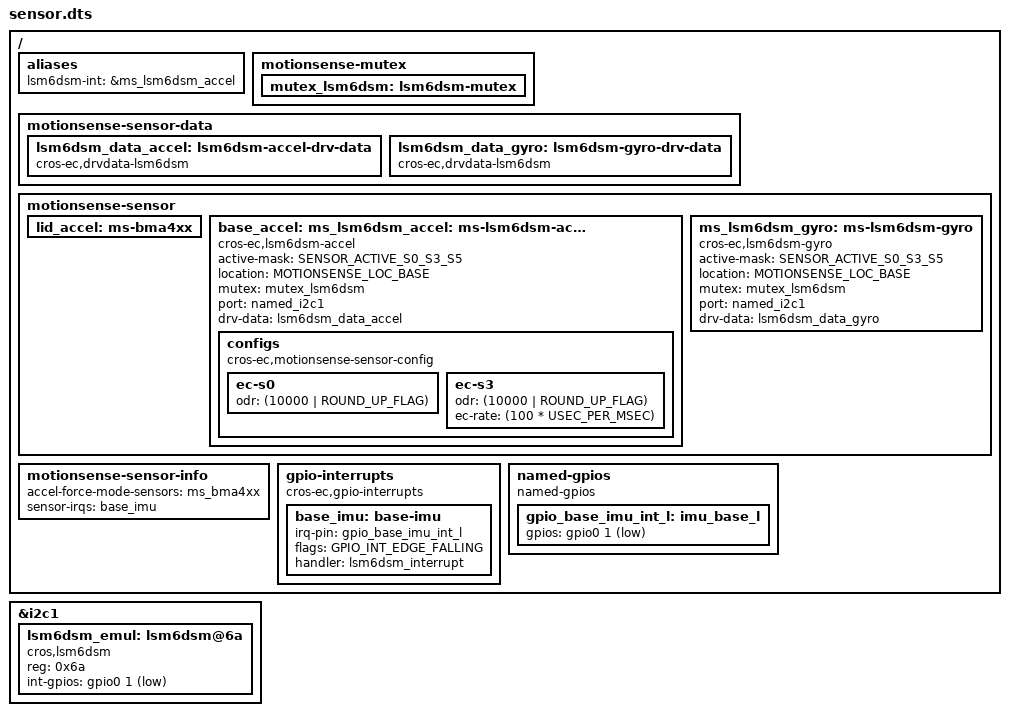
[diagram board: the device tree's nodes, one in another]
/* Copyright 2025 The ChromiumOS Authors
 * Use of this source code is governed by a BSD-style license that can be
 * found in the LICENSE file.
 */

#include "dt-bindings/gpio_defines.h"
#include <dt-bindings/motionsense/utils.h>

/ {
  aliases {
		lsm6dsm-int = &ms_lsm6dsm_accel;
		/delete-property/ bmi160-int;
		/delete-property/ bmi260-int;
		/delete-property/ tcs3400-int;
		/delete-property/ on-body-sensor;
  };

  motionsense-mutex {
		mutex_lsm6dsm: lsm6dsm-mutex {
		};
  };

  motionsense-sensor-data {
		lsm6dsm_data_accel: lsm6dsm-accel-drv-data {
			compatible = "cros-ec,drvdata-lsm6dsm";
			status = "okay";
		};

		lsm6dsm_data_gyro: lsm6dsm-gyro-drv-data {
			compatible = "cros-ec,drvdata-lsm6dsm";
			status = "okay";
		};
  };

  motionsense-sensor {

		lid_accel: ms-bma4xx {};

		base_accel: ms_lsm6dsm_accel: ms-lsm6dsm-accel {
			compatible = "cros-ec,lsm6dsm-accel";
			status = "okay";

			active-mask = "SENSOR_ACTIVE_S0_S3_S5";
			location = "MOTIONSENSE_LOC_BASE";
			mutex = <&mutex_lsm6dsm>;
			port = <&named_i2c1>;
			drv-data = <&lsm6dsm_data_accel>;
			configs {
				compatible =
					"cros-ec,motionsense-sensor-config";
				ec-s0 {
					odr = <(10000 | ROUND_UP_FLAG)>;
				};
				ec-s3 {
					odr = <(10000 | ROUND_UP_FLAG)>;
					ec-rate = <(100 * USEC_PER_MSEC)>;
				};
			};
		};

		ms_lsm6dsm_gyro: ms-lsm6dsm-gyro {
			compatible = "cros-ec,lsm6dsm-gyro";
			status = "okay";

			active-mask = "SENSOR_ACTIVE_S0_S3_S5";
			location = "MOTIONSENSE_LOC_BASE";
			mutex = <&mutex_lsm6dsm>;
			port = <&named_i2c1>;
			drv-data = <&lsm6dsm_data_gyro>;
		};
  };

	motionsense-sensor-info {
		accel-force-mode-sensors = <&ms_bma4xx>;
		sensor-irqs = <&base_imu>;
	};

	gpio-interrupts {
		compatible = "cros-ec,gpio-interrupts";

		base_imu: base-imu {
			irq-pin = <&gpio_base_imu_int_l>;
			flags = <GPIO_INT_EDGE_FALLING>;
			handler = "lsm6dsm_interrupt";
		};
	};
	named-gpios {
		compatible = "named-gpios";
		gpio_base_imu_int_l: imu_base_l {
			gpios = <&gpio0 1 (GPIO_INPUT | GPIO_ACTIVE_LOW)>;
		};
	};
};

&i2c1 {
		lsm6dsm_emul: lsm6dsm@6a {
			compatible = "cros,lsm6dsm";
			status = "okay";
			reg = <0x6a>;
			int-gpios = <&gpio0 1 GPIO_ACTIVE_LOW>;
		};
};

/delete-node/ &ms_bma255;
/delete-node/ &ms_bmi260_accel;
/delete-node/ &ms_bmi260_gyro;
/delete-node/ &ms_bmi160_accel;
/delete-node/ &ms_bmi160_gyro;
/delete-node/ &ms_lis2dw12_accel;
/delete-node/ &tcs3400_clear;
/delete-node/ &tcs3400_rgb;
/delete-node/ &accel_bmi160;
/delete-node/ &bma422_emul;
